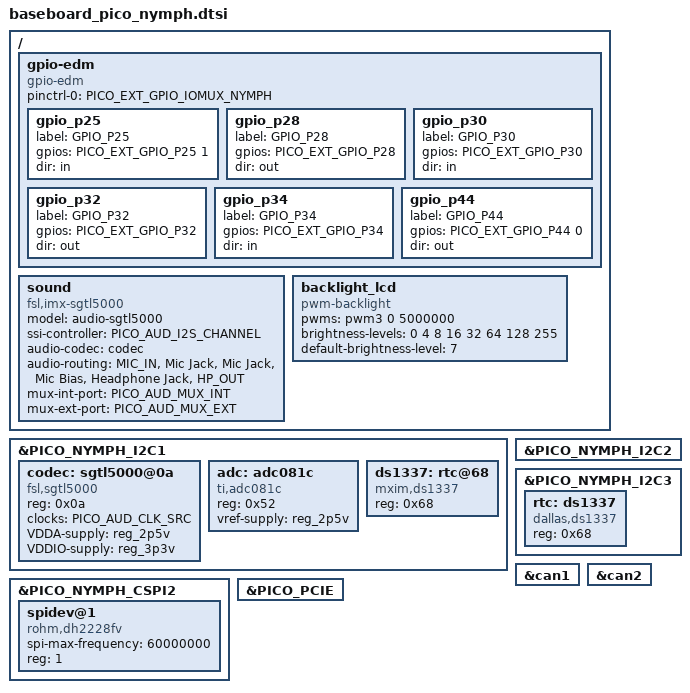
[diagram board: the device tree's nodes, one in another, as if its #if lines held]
/*
 * Copyright 2016 Technexion Ltd.
 *
 * Author: Wig Cheng <wig.cheng@technexion.com>
 *	   Richard Hu <richard.hu@technexion.com>
 *	   Tapani Utriainen <tapani@technexion.com>
 *
 * This program is free software; you can redistribute it and/or modify
 * it under the terms of the GNU General Public License version 2 as
 * published by the Free Software Foundation.
 *
 */

#include <tnmacro.h>

/ {
	gpio-edm {
		compatible = "gpio-edm";
/* custom GPIO may be from GPIO expander on CPU module */
#ifdef PICO_EXT_GPIO_IOMUX_NYMPH
		pinctrl-names = "default";
		pinctrl-0 = <PICO_EXT_GPIO_IOMUX_NYMPH>;
#endif

		/* Mikrobus */
		gpio_p25 {
			label = "GPIO_P25";
			gpios = <&PICO_EXT_GPIO_P25 1>;
			dir   = "in";
		};

		/* GPIO connector, 4 GPIOs */
		gpio_p28 {
			label = "GPIO_P28";
			gpios = <&PICO_EXT_GPIO_P28 GPIO_ACTIVE_HIGH>;
			dir   = "out";
		};
		gpio_p30 {
			label = "GPIO_P30";
			gpios = <&PICO_EXT_GPIO_P30 GPIO_ACTIVE_HIGH>;
			dir   = "in";
		};
		gpio_p32 {
			label = "GPIO_P32";
			gpios = <&PICO_EXT_GPIO_P32 GPIO_ACTIVE_HIGH>;
			dir   = "out";
		};
		gpio_p34 {
			label = "GPIO_P34";
			gpios = <&PICO_EXT_GPIO_P34 GPIO_ACTIVE_HIGH>;
			dir   = "in";
		};

		/* LED */
		gpio_p44 {
			label = "GPIO_P44";
			gpios = <&PICO_EXT_GPIO_P44 0>;
			dir   = "out";
		};
	};

	sound {
		compatible = "fsl,imx-sgtl5000",
			     "fsl,imx-audio-sgtl5000";
		model = "audio-sgtl5000";
		ssi-controller = <&PICO_AUD_I2S_CHANNEL>;
		audio-codec = <&codec>;
		audio-routing =
			"MIC_IN", "Mic Jack",
			"Mic Jack", "Mic Bias",
			"Headphone Jack", "HP_OUT";
#if defined(PICO_AUD_MUX_INT) && defined(PICO_AUD_MUX_EXT)
		mux-int-port = <PICO_AUD_MUX_INT>;
		mux-ext-port = <PICO_AUD_MUX_EXT>;
#else
		fsl,no-audmux = "true";
#endif
	};

	backlight_lcd {
		compatible = "pwm-backlight";
		pwms = <&pwm3 0 5000000>;
		brightness-levels = <0 4 8 16 32 64 128 255>;
		default-brightness-level = <7>;
	};

};

&PICO_NYMPH_I2C1 {
	status = "okay";

	codec: sgtl5000@0a {
		compatible = "fsl,sgtl5000";
		reg = <0x0a>;
		clocks = <&PICO_AUD_CLK_SRC>;
		VDDA-supply = <&reg_2p5v>;
		VDDIO-supply = <&reg_3p3v>;
	};

	adc: adc081c {
		compatible = "ti,adc081c";
		reg = <0x52>;
		vref-supply = <&reg_2p5v>;
	};
	
	ds1337: rtc@68 {
		compatible = "mxim,ds1337";
		reg = <0x68>;
	};		
};

&PICO_NYMPH_I2C2 {
	status = "okay";
};

&PICO_NYMPH_I2C3 {
	status = "okay";

	rtc: ds1337 {
		compatible = "dallas,ds1337";
		reg = <0x68>;
	};
};

&can1 {
	status = "okay";
};

&can2 {
	status = "okay";
};

&PICO_NYMPH_CSPI2 {
	status = "okay";

	spidev@1 {
		compatible = "rohm,dh2228fv";
		spi-max-frequency = <60000000>;
		reg = <1>;
	};
};

#ifdef PICO_PCIE
&PICO_PCIE {
	status = "okay";
};
#endif
